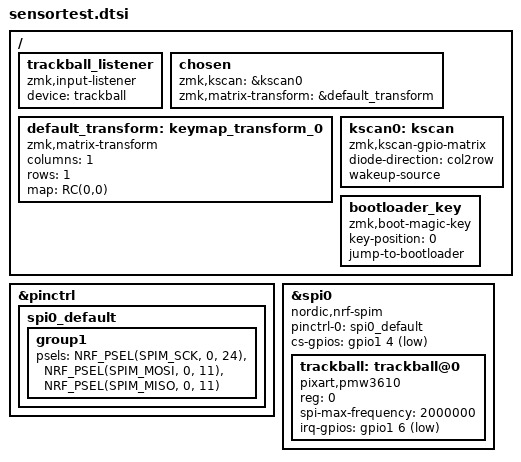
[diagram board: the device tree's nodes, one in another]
#include <dt-bindings/zmk/matrix_transform.h>

&pinctrl {
    spi0_default: spi0_default {
        group1 {
            psels = <NRF_PSEL(SPIM_SCK, 0, 24)>,
                <NRF_PSEL(SPIM_MOSI, 0, 11)>,
                <NRF_PSEL(SPIM_MISO, 0, 11)>;
        };
    };

//    spi0_sleep: spi0_sleep {
//        group1 {
//            psels = <NRF_PSEL(SPIM_SCK, 0, 24)>,
//                <NRF_PSEL(SPIM_MOSI, 0, 11)>,
//                <NRF_PSEL(SPIM_MISO, 0, 11)>;
//            low-power-enable;
//        };
//    };
};

&spi0 {
    status = "okay";
    compatible = "nordic,nrf-spim";
    pinctrl-0 = <&spi0_default>;
//   pinctrl-1 = <&spi0_sleep>;
//   pinctrl-names = "default", "sleep";
    pinctrl-names = "default";
    cs-gpios = <&gpio1 4 GPIO_ACTIVE_LOW>;

    trackball: trackball@0 {
        status = "okay";
        compatible = "pixart,pmw3610";
        reg = <0>;
        spi-max-frequency = <2000000>;
        irq-gpios = <&gpio1 6 (GPIO_ACTIVE_LOW | GPIO_PULL_UP)>;

        /*   optional features   */
        // snipe-layers = <1>;
        // scroll-layers = <2 3>;
        // automouse-layer = <4>;
    };
};

/ {
  trackball_listener {
    compatible = "zmk,input-listener";
    device = <&trackball>;

  };

    chosen {
        zmk,kscan = &kscan0;
        zmk,matrix-transform = &default_transform;
    };

    default_transform: keymap_transform_0 {
        compatible = "zmk,matrix-transform";
        columns = <1>;
        rows = <1>;
        map = <
RC(0,0)
        > ;
    };

    kscan0: kscan {
        compatible = "zmk,kscan-gpio-matrix";
        diode-direction = "col2row";
        wakeup-source;
    };

    bootloader_key: bootloader_key  {
        compatible = "zmk,boot-magic-key";
        key-position = <0>;
        jump-to-bootloader;
        status = "okay";
    };
};
